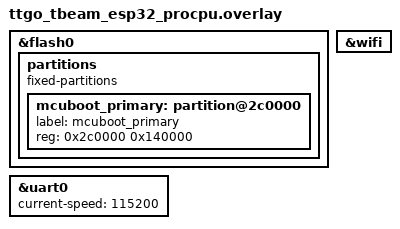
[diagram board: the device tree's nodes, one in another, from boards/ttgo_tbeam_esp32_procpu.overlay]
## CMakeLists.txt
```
cmake_minimum_required(VERSION 3.20)
find_package(Zephyr REQUIRED HINTS $ENV{ZEPHYR_BASE})

set(CMAKE_EXPORT_COMPILE_COMMANDS ON)

project(z_lora)

target_sources(app PRIVATE src/main.c)
```

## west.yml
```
manifest:
  remotes:
    - name: zephyrproject-rtos
      url-base: https://github.com/zephyrproject-rtos
  projects:
    - name: zephyr
      remote: zephyrproject-rtos
      revision: v4.2.0
      path: zephyr
      west-commands: scripts/west-commands.yml
      import:
        name-allowlist:
          - hal_espressif
          - loramac-node
          - wpa_supplicant
          - mbedtls
          - mcuboot
  self:
    path: .
```

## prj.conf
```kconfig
# Console / UART
CONFIG_SERIAL=y
CONFIG_CONSOLE=y
CONFIG_UART_CONSOLE=y
CONFIG_LOG_BACKEND_UART=y

# Shell
CONFIG_SHELL=n
#CONFIG_SHELL_BACKEND_SERIAL=n
#CONFIG_SHELL_STACK_SIZE=3072

# Logging
CONFIG_LOG=n
#CONFIG_LOG_MODE_DEFERRED=n
#CONFIG_LOG_MODE_IMMEDIATE=y
#CONFIG_LOG_MODE_OVERFLOW=y
#CONFIG_LOG_BUFFER_SIZE=16384
#CONFIG_LOG_DEFAULT_LEVEL=3
#CONFIG_LOG_PRINTK=n
#CONFIG_LOG_RUNTIME_FILTERING=y
#CONFIG_LOG_BACKEND_SHOW_COLOR=n
#CONFIG_SHELL_VT100_COLORS=n


# Backends: only shell
#CONFIG_SHELL_LOG_BACKEND=y
#CONFIG_LOG_BACKEND_UART=n
#CONFIG_LOG_BACKEND_RTT=n
#CONFIG_LOG_BACKEND_SWO=n

CONFIG_MAIN_STACK_SIZE=8192
CONFIG_ISR_STACK_SIZE=4096
CONFIG_IDLE_STACK_SIZE=1024


CONFIG_LORA=y
CONFIG_LORA_SX127X=y
```

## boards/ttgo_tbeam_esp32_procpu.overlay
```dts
/* partitions live under flash0 */
&flash0 {
    partitions {
        compatible = "fixed-partitions";
        #address-cells = <1>;
        #size-cells = <1>;

        mcuboot_primary: partition@2c0000 {
            label = "mcuboot_primary";
            reg = <0x2c0000 0x140000>; /* ends at 0x400000 */
        };
    };
};

&wifi {
    status = "okay";
};

&uart0 {
    status = "okay";
    current-speed = <115200>;
};
```

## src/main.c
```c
#include <zephyr/kernel.h>
//#include <zephyr/logging/log.h>
#include <zephyr/device.h>
#include <zephyr/devicetree.h>
#include <zephyr/drivers/lora.h>
#include <zephyr/console/console.h>

#include <zephyr/drivers/uart.h>
#define UART_CONSOLE_NODE DT_CHOSEN(zephyr_console)
static const struct device *const uart_dev = DEVICE_DT_GET(UART_CONSOLE_NODE);

static void uart_write_sync(const char *s, size_t n)
{
	for (size_t i = 0; i < n; i++) {
		uart_poll_out(uart_dev, s[i]);
		k_msleep(1);
	}
}

//LOG_MODULE_REGISTER(main, LOG_LEVEL_DBG);

#define LORA_NODE DT_NODELABEL(lora0)

static struct lora_modem_config cfg = {
	.frequency = 433175000, /* eu433 ch0; try also 433375000, 433575000 */
	// .frequency = 433375000, /* eu433 ch1; try also 433375000, 433575000 */
	// .frequency = 433575000, /* eu433 ch2; try also 433375000, 433575000 */

	.bandwidth = BW_250_KHZ,
	.datarate = SF_11, /* try SF7..SF12 to match transmitters */
	.coding_rate = CR_4_6,
	//.datarate = SF_7,
	//.coding_rate = CR_4_5,
	.preamble_len = 8,
	.tx_power = 10, /* unused in RX */
	.tx = false,
	.iq_inverted = false, /* set true to watch downlinks */
	.public_network = false,
};

#define DUMP_MAX_STR 2048

static void lora_dump(const uint8_t *buf, size_t len, int rssi, int snr)
{
	len = MIN(len, 256);

	static char out[DUMP_MAX_STR];
	size_t pos = 0;

	pos += snprintk(out + pos, sizeof(out) - pos, "\nRSSI: %d dBm    SNR: %d dB    SIZE: %u\n", rssi, snr, (unsigned)len);

	for (size_t off = 0; off < len && pos < sizeof(out) - 2; off += 16) {
		size_t n = MIN(16, len - off);

		pos += snprintk(out + pos, sizeof(out) - pos, "%08x  ", (unsigned)off);

		for (size_t i = 0; i < 16; i++) {
			if (i < n)
				pos += snprintk(out + pos, sizeof(out) - pos, "%02x", buf[off + i]);
			else
				pos += snprintk(out + pos, sizeof(out) - pos, "  ");
			pos += snprintk(out + pos, sizeof(out) - pos, (i == 7) ? "  " : " ");
		}

		out[pos++] = ' ';
		out[pos++] = '|';
		for (size_t i = 0; i < n && pos < sizeof(out) - 2; i++) {
			uint8_t c = buf[off + i];
			out[pos++] = (c >= 32 && c < 127) ? (char)c : '.';
		}
		out[pos++] = '|';
		out[pos++] = '\n';
	}

	uart_write_sync(out, pos);
}

static int clamp_int(int value, int min_value, int max_value)
{
	if (value < min_value) {
		return min_value;
	}
	if (value > max_value) {
		return max_value;
	}
	return value;
}

int main(void)
{
	k_msleep(100);
	// psram_backend_enable();

	const struct device *dev = DEVICE_DT_GET(LORA_NODE);

	if (!device_is_ready(dev)) {
		printk("Lora device not ready!\n");
		k_msleep(5000);

		return 0;
	}

	if (lora_config(dev, &cfg) != 0) {
		printk("lora_config failed\n");
		k_msleep(5000);

		return 0;
	}

	static uint8_t buffer[1024];

	while (1) {
		int16_t rssi = 0;
		int8_t snr = 0;

		int rc = lora_recv(dev, buffer, 255, K_FOREVER, &rssi, &snr);

		if (rc > 0) {
			lora_dump(buffer, (size_t)clamp_int(rc, 0, sizeof(buffer)), (int)rssi, (int)snr);
		} else if (rc < 0) {
			printk("RX: error: %d\n", rc);
		}
	}
}
```

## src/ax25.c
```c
#include <stdint.h>
#include <stdbool.h>

#define AX25_MAX_DIGIS 8

typedef struct {
	char callsign[7];
	uint8_t ssid; // 0-15
	uint8_t raw_ssid; //
	bool last;
} ax25_addr_t;

typedef struct {
	ax25_addr_t dest;
	ax25_addr_t src;
	ax25_addr_t digis[AX25_MAX_DIGIS];
	uint8_t num_digis;

	uint8_t control;
	bool is_u_frame;
	bool is_s_frame;
	bool is_i_frame;

	uint8_t pid;
	const uint8_t *info;
	uint16_t info_len;

} ax25_frame_t;

/* -------- CRC-CCITT (X.25) LSB-first: init 0xFFFF, poly 0x8408, final ones' complement -------- */
static uint16_t ax25_crc_update(uint16_t crc, uint8_t byte)
{
	crc ^= byte;
	for (int i = 0; i < 8; i++) {
		if (crc & 0x0001) {
			crc = (crc >> 1) ^ 0x8408;
		} else {
			crc >>= 1;
		}
	}
	return crc;
}

static bool ax25_check_fcs(const uint8_t *buf, size_t len_no_flags)
{
	if (len_no_flags < 3) {
		return false;
	} // at least 1 byte + 2-byte FCS
	size_t payload_len = len_no_flags - 2;
	uint16_t crc = 0xFFFF;
	for (size_t i = 0; i < payload_len; i++) {
		crc = ax25_crc_update(crc, buf[i]);
	}
	crc = ~crc; // ones' complement

	uint16_t fcs_rx = (uint16_t)buf[payload_len] | ((uint16_t)buf[payload_len + 1] << 8); // LSB first on air
	return crc == fcs_rx;
}

/* -------- Address decoding --------
   Each address is 7 bytes: 6 callsign chars and 1 SSID/flags octet.
   All 7 bytes are left-shifted by 1 bit on-air; bit0 of the 7th octet is the Extension (E) bit.
*/
static void parse_callsign(const uint8_t *addr7, ax25_addr_t *out)
{
	// callsign chars are upper-case ASCII left-shifted by 1; pad is space.
	int end = 6;
	for (int i = 0; i < 6; i++) {
		char c = (char)(addr7[i] >> 1);
		out->callsign[i] = c;
		if (c != ' ') {
			end = i + 1;
		}
	}
	out->callsign[end] = '\0';

	uint8_t ssid_oct = addr7[6];
	out->raw_ssid = ssid_oct;
	out->last = (ssid_oct & 0x01) ? true : false; // E-bit
	out->ssid = (uint8_t)((ssid_oct >> 1) & 0x0F); // 4-bit SSID, 0..15
}

/* Returns bytes consumed from buf, or 0 on error. Fills dest, src, digis, num_digis. */
static size_t ax25_parse_addresses(const uint8_t *buf, size_t len, ax25_frame_t *f)
{
	if (len < 14) {
		return 0;
	}

	parse_callsign(buf + 0, &f->dest);
	parse_callsign(buf + 7, &f->src);

	size_t off = 14;
	f->num_digis = 0;

	// If 'src.last' is not set, there are digipeaters (up to 8), each 7 bytes, last has E-bit set.
	if (!f->src.last) {
		while (off + 7 <= len && f->num_digis < AX25_MAX_DIGIS) {
			parse_callsign(buf + off, &f->digis[f->num_digis]);
			f->num_digis++;
			off += 7;
			if (f->digis[f->num_digis - 1].last) {
				break;
			}
		}
		if (f->num_digis == 0) {
			return 0;
		} // malformed: no terminating E-bit found
		if (!f->digis[f->num_digis - 1].last) {
			return 0;
		} // malformed: not terminated
	}

	return off;
}

/* -------- Frame type helpers -------- */
static void classify_control(uint8_t ctl, bool *is_u, bool *is_s, bool *is_i)
{
	// I-frame: bit0 == 0
	// S-frame: 0b01 in bits1..0
	// U-frame: 0b11 in bits1..0
	*is_i = ((ctl & 0x01) == 0);
	*is_s = ((ctl & 0x03) == 0x01);
	*is_u = ((ctl & 0x03) == 0x03);
}

/* -------- Top-level decode -------- */
bool ax25_decode(const uint8_t *frame_bytes_no_flags, size_t len, ax25_frame_t *out)
{
	if (len < 16) {
		return false;
	} // minimal: 14 addr + 1 ctl + 1 FCS? But FCS is 2 bytes.

	if (!ax25_check_fcs(frame_bytes_no_flags, len)) {
		return false;
	}

	size_t addr_len = ax25_parse_addresses(frame_bytes_no_flags, len - 2, out);
	if (addr_len == 0) {
		return false;
	}

	if (addr_len + 1 > len - 2) {
		return false;
	}
	out->control = frame_bytes_no_flags[addr_len + 0];

	classify_control(out->control, &out->is_u_frame, &out->is_s_frame, &out->is_i_frame);

	size_t off = addr_len + 1;
	out->pid = 0;
	out->info = NULL;
	out->info_len = 0;

	// PID present for I-frames and most U-frames, also UI (0x03) specifically.
	bool pid_present = out->is_i_frame || (out->is_u_frame && out->control == 0x03);
	if (pid_present) {
		if (off + 1 > len - 2) {
			return false;
		}
		out->pid = frame_bytes_no_flags[off++];
		if (off <= len - 2) {
			out->info = frame_bytes_no_flags + off;
			out->info_len = (uint16_t)((len - 2) - off);
		}
	} else {
		// Supervisory or other U-frames without PID
		if (off <= len - 2) {
			out->info = frame_bytes_no_flags + off;
			out->info_len = (uint16_t)((len - 2) - off);
		}
	}

	return true;
}
```

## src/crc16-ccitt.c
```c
#include <stdint.h>
#include <stddef.h>

uint16_t crc_ccitt_calc_first(const uint8_t *buffer, size_t len);
uint16_t crc_ccitt_calc_next(uint16_t crc, const uint8_t *buffer, size_t len);

static uint16_t crc_ccitt_table[256] = {
	0x0000, 0x1189, 0x2312, 0x329b, 0x4624, 0x57ad, 0x6536, 0x74bf, 0x8c48, 0x9dc1, 0xaf5a, 0xbed3, 0xca6c, 0xdbe5, 0xe97e, 0xf8f7, 0x1081, 0x0108, 0x3393,
	0x221a, 0x56a5, 0x472c, 0x75b7, 0x643e, 0x9cc9, 0x8d40, 0xbfdb, 0xae52, 0xdaed, 0xcb64, 0xf9ff, 0xe876, 0x2102, 0x308b, 0x0210, 0x1399, 0x6726, 0x76af,
	0x4434, 0x55bd, 0xad4a, 0xbcc3, 0x8e58, 0x9fd1, 0xeb6e, 0xfae7, 0xc87c, 0xd9f5, 0x3183, 0x200a, 0x1291, 0x0318, 0x77a7, 0x662e, 0x54b5, 0x453c, 0xbdcb,
	0xac42, 0x9ed9, 0x8f50, 0xfbef, 0xea66, 0xd8fd, 0xc974, 0x4204, 0x538d, 0x6116, 0x709f, 0x0420, 0x15a9, 0x2732, 0x36bb, 0xce4c, 0xdfc5, 0xed5e, 0xfcd7,
	0x8868, 0x99e1, 0xab7a, 0xbaf3, 0x5285, 0x430c, 0x7197, 0x601e, 0x14a1, 0x0528, 0x37b3, 0x263a, 0xdecd, 0xcf44, 0xfddf, 0xec56, 0x98e9, 0x8960, 0xbbfb,
	0xaa72, 0x6306, 0x728f, 0x4014, 0x519d, 0x2522, 0x34ab, 0x0630, 0x17b9, 0xef4e, 0xfec7, 0xcc5c, 0xddd5, 0xa96a, 0xb8e3, 0x8a78, 0x9bf1, 0x7387, 0x620e,
	0x5095, 0x411c, 0x35a3, 0x242a, 0x16b1, 0x0738, 0xffcf, 0xee46, 0xdcdd, 0xcd54, 0xb9eb, 0xa862, 0x9af9, 0x8b70, 0x8408, 0x9581, 0xa71a, 0xb693, 0xc22c,
	0xd3a5, 0xe13e, 0xf0b7, 0x0840, 0x19c9, 0x2b52, 0x3adb, 0x4e64, 0x5fed, 0x6d76, 0x7cff, 0x9489, 0x8500, 0xb79b, 0xa612, 0xd2ad, 0xc324, 0xf1bf, 0xe036,
	0x18c1, 0x0948, 0x3bd3, 0x2a5a, 0x5ee5, 0x4f6c, 0x7df7, 0x6c7e, 0xa50a, 0xb483, 0x8618, 0x9791, 0xe32e, 0xf2a7, 0xc03c, 0xd1b5, 0x2942, 0x38cb, 0x0a50,
	0x1bd9, 0x6f66, 0x7eef, 0x4c74, 0x5dfd, 0xb58b, 0xa402, 0x9699, 0x8710, 0xf3af, 0xe226, 0xd0bd, 0xc134, 0x39c3, 0x284a, 0x1ad1, 0x0b58, 0x7fe7, 0x6e6e,
	0x5cf5, 0x4d7c, 0xc60c, 0xd785, 0xe51e, 0xf497, 0x8028, 0x91a1, 0xa33a, 0xb2b3, 0x4a44, 0x5bcd, 0x6956, 0x78df, 0x0c60, 0x1de9, 0x2f72, 0x3efb, 0xd68d,
	0xc704, 0xf59f, 0xe416, 0x90a9, 0x8120, 0xb3bb, 0xa232, 0x5ac5, 0x4b4c, 0x79d7, 0x685e, 0x1ce1, 0x0d68, 0x3ff3, 0x2e7a, 0xe70e, 0xf687, 0xc41c, 0xd595,
	0xa12a, 0xb0a3, 0x8238, 0x93b1, 0x6b46, 0x7acf, 0x4854, 0x59dd, 0x2d62, 0x3ceb, 0x0e70, 0x1ff9, 0xf78f, 0xe606, 0xd49d, 0xc514, 0xb1ab, 0xa022, 0x92b9,
	0x8330, 0x7bc7, 0x6a4e, 0x58d5, 0x495c, 0x3de3, 0x2c6a, 0x1ef1, 0x0f78
};

static uint16_t crc_ccitt_byte(uint16_t crc, const uint8_t byte)
{
	return (crc >> 8) ^ crc_ccitt_table[(crc ^ byte) & 0xFF];
}

uint16_t crc_ccitt_calc_first(const uint8_t *buffer, size_t len)
{
	return crc_ccitt_calc_next(0xFFFF, buffer, len);
}

uint16_t crc_ccitt_calc_next(uint16_t crc, const uint8_t *buffer, size_t len)
{
	for (size_t i = 0; i < len; i++) {
		crc = crc_ccitt_byte(crc, *buffer);
		buffer++;
	}

	return crc;
}
```

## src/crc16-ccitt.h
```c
#ifndef CRC16_CCITT_H
#define CRC16_CCITT_H
#include <stdint.h>
#include <stddef.h>

uint16_t crc_ccitt_calc_first(const uint8_t *buffer, size_t len);
uint16_t crc_ccitt_calc_next(uint16_t crc, const uint8_t *buffer, size_t len);

#endif
```
